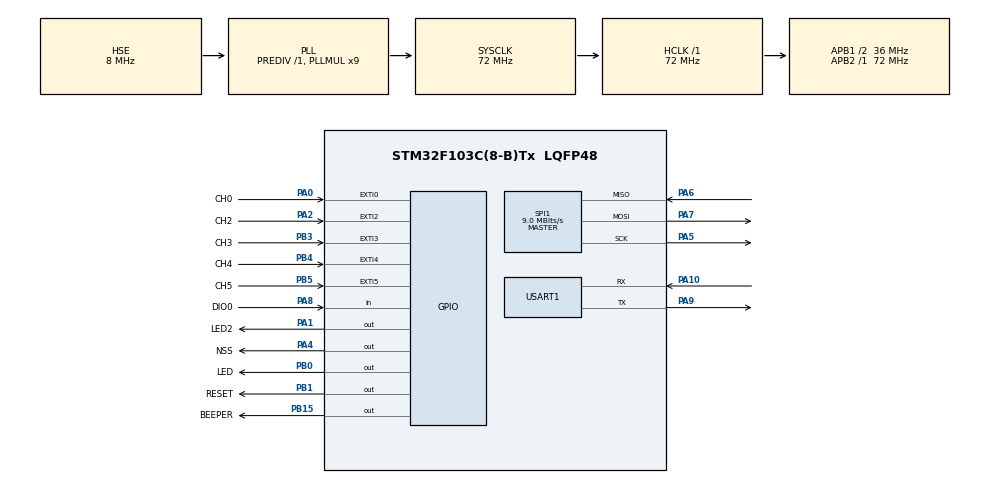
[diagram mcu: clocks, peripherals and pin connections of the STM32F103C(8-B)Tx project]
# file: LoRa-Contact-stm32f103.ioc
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IWDG.Prescaler=IWDG_PRESCALER_16
Mcu.Family=STM32F1
Mcu.Name=STM32F103C(8-B)Tx
Mcu.Package=LQFP48
NVIC.EXTI0_IRQn=true\:0\:0\:false\:false\:true\:true\:true\:true
NVIC.EXTI2_IRQn=true\:0\:0\:false\:false\:true\:true\:true\:true
NVIC.EXTI3_IRQn=true\:0\:0\:false\:false\:true\:true\:true\:true
NVIC.EXTI4_IRQn=true\:0\:0\:false\:false\:true\:true\:true\:true
NVIC.EXTI9_5_IRQn=true\:0\:0\:false\:false\:true\:true\:true\:true
NVIC.PriorityGroup=NVIC_PRIORITYGROUP_4
PA0-WKUP.GPIO_Label=CH0
PA0-WKUP.GPIO_ModeDefaultEXTI=GPIO_MODE_IT_FALLING
PA0-WKUP.GPIO_PuPd=GPIO_PULLUP
PA0-WKUP.Signal=GPXTI0
PA1.GPIO_Label=LED2
PA1.Signal=GPIO_Output
PA10.Mode=Asynchronous
PA10.Signal=USART1_RX
PA13.Mode=Serial_Wire
PA13.Signal=SYS_JTMS-SWDIO
PA14.Mode=Serial_Wire
PA14.Signal=SYS_JTCK-SWCLK
PA2.GPIO_Label=CH2
PA2.GPIO_ModeDefaultEXTI=GPIO_MODE_IT_FALLING
PA2.GPIO_PuPd=GPIO_PULLUP
PA2.Signal=GPXTI2
PA4.GPIO_Label=NSS
PA4.GPIO_PuPd=GPIO_NOPULL
PA4.PinState=GPIO_PIN_SET
PA4.Signal=GPIO_Output
PA5.Mode=Full_Duplex_Master
PA5.Signal=SPI1_SCK
PA6.Mode=Full_Duplex_Master
PA6.Signal=SPI1_MISO
PA7.Mode=Full_Duplex_Master
PA7.Signal=SPI1_MOSI
PA8.GPIO_Label=DIO0
PA8.GPIO_PuPd=GPIO_PULLUP
PA8.Signal=GPIO_Input
PA9.Mode=Asynchronous
PA9.Signal=USART1_TX
PB0.GPIO_Label=LED
PB0.Signal=GPIO_Output
PB1.GPIO_Label=RESET
PB1.PinState=GPIO_PIN_SET
PB1.Signal=GPIO_Output
PB15.GPIO_Label=BEEPER
PB15.GPIO_ModeDefaultOutputPP=GPIO_MODE_OUTPUT_OD
PB15.GPIO_PuPd=GPIO_NOPULL
PB15.PinState=GPIO_PIN_SET
PB15.Signal=GPIO_Output
PB3.GPIO_Label=CH3
PB3.GPIO_ModeDefaultEXTI=GPIO_MODE_IT_FALLING
PB3.GPIO_PuPd=GPIO_PULLUP
PB3.Signal=GPXTI3
PB4.GPIO_Label=CH4
PB4.GPIO_ModeDefaultEXTI=GPIO_MODE_IT_FALLING
PB4.GPIO_PuPd=GPIO_PULLUP
PB4.Signal=GPXTI4
PB5.GPIO_Label=CH5
PB5.GPIO_ModeDefaultEXTI=GPIO_MODE_IT_FALLING
PB5.GPIO_PuPd=GPIO_PULLUP
PB5.Signal=GPXTI5
PD0-OSC_IN.Mode=HSE-External-Oscillator
PD0-OSC_IN.Signal=RCC_OSC_IN
PD1-OSC_OUT.Mode=HSE-External-Oscillator
PD1-OSC_OUT.Signal=RCC_OSC_OUT
ProjectManager.HeapSize=0x200
ProjectManager.StackSize=0x400
ProjectManager.TargetToolchain=STM32CubeIDE
RCC.AHBFreq_Value=72000000
RCC.APB1CLKDivider=RCC_HCLK_DIV2
RCC.APB1Freq_Value=36000000
RCC.APB1TimFreq_Value=72000000
RCC.APB2Freq_Value=72000000
RCC.APB2TimFreq_Value=72000000
RCC.HCLKFreq_Value=72000000
RCC.PLLMUL=RCC_PLL_MUL9
RCC.PLLSourceVirtual=RCC_PLLSOURCE_HSE
RCC.SYSCLKFreq_VALUE=72000000
RCC.SYSCLKSource=RCC_SYSCLKSOURCE_PLLCLK
RCC.USBFreq_Value=72000000
SPI1.BaudRatePrescaler=SPI_BAUDRATEPRESCALER_8
SPI1.CalculateBaudRate=9.0 MBits/s
SPI1.Direction=SPI_DIRECTION_2LINES
SPI1.Mode=SPI_MODE_MASTER
SPI1.VirtualType=VM_MASTER
USART1.VirtualMode=VM_ASYNC
VP_IWDG_VS_IWDG.Mode=IWDG_Activate
board=custom

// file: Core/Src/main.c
/* USER CODE BEGIN Header */
/**
  ******************************************************************************
  * @file           : main.c
  * @brief          : Main program body
  * author 			: Bazhen Paseka
  * 13-July-2022
  ******************************************************************************
  * @attention
  *
  * Copyright (c) 2022 STMicroelectronics.
  * All rights reserved.
  *
  * This software is licensed under terms that can be found in the LICENSE file
  * in the root directory of this software component.
  * If no LICENSE file comes with this software, it is provided AS-IS.
  *
  ******************************************************************************
  */
/* USER CODE END Header */
#include "main.h"
#include "iwdg.h"
#include "spi.h"
#include "usart.h"
#include "gpio.h"

/* USER CODE BEGIN Includes */

	#include "LoRa-Contact_SM.h"

/* USER CODE END Includes */

void SystemClock_Config(void);

int main(void)
{

  /* MCU Configuration--------------------------------------------------------*/

  /* Reset of all peripherals, Initializes the Flash interface and the Systick. */
  HAL_Init();

  /* Configure the system clock */
  SystemClock_Config();

  /* Initialize all configured peripherals */
  MX_GPIO_Init();
  MX_SPI1_Init();
  MX_USART1_UART_Init();
  MX_IWDG_Init();
  /* USER CODE BEGIN 2 */

  	  LoRa_Contact_Init();

  /* USER CODE END 2 */

  /* Infinite loop */
  /* USER CODE BEGIN WHILE */
  while (1)
  {
	  LoRa_Contact_Main();

    /* USER CODE END WHILE */

  }
}

void SystemClock_Config(void)
{
  RCC_OscInitTypeDef RCC_OscInitStruct = {0};
  RCC_ClkInitTypeDef RCC_ClkInitStruct = {0};

  /** Initializes the RCC Oscillators according to the specified parameters
  * in the RCC_OscInitTypeDef structure.
  */
  RCC_OscInitStruct.OscillatorType = RCC_OSCILLATORTYPE_LSI|RCC_OSCILLATORTYPE_HSE;
  RCC_OscInitStruct.HSEState = RCC_HSE_ON;
  RCC_OscInitStruct.HSEPredivValue = RCC_HSE_PREDIV_DIV1;
  RCC_OscInitStruct.HSIState = RCC_HSI_ON;
  RCC_OscInitStruct.LSIState = RCC_LSI_ON;
  RCC_OscInitStruct.PLL.PLLState = RCC_PLL_ON;
  RCC_OscInitStruct.PLL.PLLSource = RCC_PLLSOURCE_HSE;
  RCC_OscInitStruct.PLL.PLLMUL = RCC_PLL_MUL9;
  if (HAL_RCC_OscConfig(&RCC_OscInitStruct) != HAL_OK)
  {
    Error_Handler();
  }

  /** Initializes the CPU, AHB and APB buses clocks
  */
  RCC_ClkInitStruct.ClockType = RCC_CLOCKTYPE_HCLK|RCC_CLOCKTYPE_SYSCLK
                              |RCC_CLOCKTYPE_PCLK1|RCC_CLOCKTYPE_PCLK2;
  RCC_ClkInitStruct.SYSCLKSource = RCC_SYSCLKSOURCE_PLLCLK;
  RCC_ClkInitStruct.AHBCLKDivider = RCC_SYSCLK_DIV1;
  RCC_ClkInitStruct.APB1CLKDivider = RCC_HCLK_DIV2;
  RCC_ClkInitStruct.APB2CLKDivider = RCC_HCLK_DIV1;

  if (HAL_RCC_ClockConfig(&RCC_ClkInitStruct, FLASH_LATENCY_2) != HAL_OK)
  {
    Error_Handler();
  }
}

void Error_Handler(void)
{
  __disable_irq();
  while (1)
  {
  }
}
